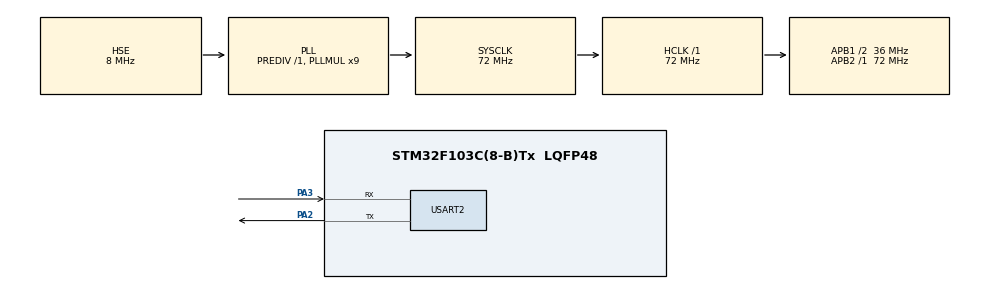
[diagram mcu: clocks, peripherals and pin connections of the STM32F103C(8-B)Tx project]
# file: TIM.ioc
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Mcu.Family=STM32F1
Mcu.Name=STM32F103C(8-B)Tx
Mcu.Package=LQFP48
NVIC.PriorityGroup=NVIC_PRIORITYGROUP_4
NVIC.TIM4_IRQn=true\:0\:0\:false\:false\:true\:true\:true\:true
NVIC.USART2_IRQn=true\:0\:0\:false\:false\:true\:true\:true\:true
PA13.Mode=Serial_Wire
PA13.Signal=SYS_JTMS-SWDIO
PA14.Mode=Serial_Wire
PA14.Signal=SYS_JTCK-SWCLK
PA2.Mode=Asynchronous
PA2.Signal=USART2_TX
PA3.Mode=Asynchronous
PA3.Signal=USART2_RX
PD0-OSC_IN.Mode=HSE-External-Oscillator
PD0-OSC_IN.Signal=RCC_OSC_IN
PD1-OSC_OUT.Mode=HSE-External-Oscillator
PD1-OSC_OUT.Signal=RCC_OSC_OUT
ProjectManager.HeapSize=0x200
ProjectManager.StackSize=0x400
ProjectManager.TargetToolchain=CMake
RCC.AHBFreq_Value=72000000
RCC.APB1CLKDivider=RCC_HCLK_DIV2
RCC.APB1Freq_Value=36000000
RCC.APB1TimFreq_Value=72000000
RCC.APB2Freq_Value=72000000
RCC.APB2TimFreq_Value=72000000
RCC.HCLKFreq_Value=72000000
RCC.PLLMUL=RCC_PLL_MUL9
RCC.PLLSourceVirtual=RCC_PLLSOURCE_HSE
RCC.SYSCLKFreq_VALUE=72000000
RCC.SYSCLKSource=RCC_SYSCLKSOURCE_PLLCLK
RCC.USBFreq_Value=72000000
TIM4.Period=10000-1
TIM4.Prescaler=7200-1
USART2.VirtualMode=VM_ASYNC
VP_TIM4_VS_ClockSourceINT.Mode=Internal
board=custom

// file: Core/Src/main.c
/* USER CODE BEGIN Header */
/**
  ******************************************************************************
  * @file           : main.c
  * @brief          : Main program body
  ******************************************************************************
  * @attention
  *
  * Copyright (c) 2026 STMicroelectronics.
  * All rights reserved.
  *
  * This software is licensed under terms that can be found in the LICENSE file
  * in the root directory of this software component.
  * If no LICENSE file comes with this software, it is provided AS-IS.
  *
  ******************************************************************************
  */
/* USER CODE END Header */
#include "main.h"

/* USER CODE BEGIN Includes */
#include "stdio.h"              /* 标准输入输出库，用于 sprintf 格式化字符串 */
#include "stm32f1xx_hal_tim.h"  /* TIM 定时器 HAL 库头文件 */
#include "string.h"             /* 字符串操作库，用于 strlen 获取字符串长度 */
/* USER CODE END Includes */

TIM_HandleTypeDef htim4;

UART_HandleTypeDef huart2;

void SystemClock_Config(void);
static void MX_GPIO_Init(void);
static void MX_TIM4_Init(void);
static void MX_USART2_UART_Init(void);

/* USER CODE BEGIN 0 */
char data[] = "一秒过去了";  /* 定时器溢出时通过串口发送的字符串 */

/* TIM 定时器溢出回调：每秒触发一次 */
void HAL_TIM_PeriodElapsedCallback(TIM_HandleTypeDef *htim){
  if(htim == &htim4){
    HAL_UART_Transmit_IT(&huart2, (uint8_t*)data, strlen(data));  /* 串口发送"一秒过去了" */
  }
}
/* USER CODE END 0 */

int main(void)
{

  /* MCU Configuration--------------------------------------------------------*/

  /* Reset of all peripherals, Initializes the Flash interface and the Systick. */
  HAL_Init();

  /* Configure the system clock */
  SystemClock_Config();

  /* Initialize all configured peripherals */
  MX_GPIO_Init();
  MX_TIM4_Init();
  MX_USART2_UART_Init();
  /* USER CODE BEGIN 2 */
  HAL_TIM_Base_Start_IT(&htim4);  /* 启动 TIM4 定时器，使能溢出中断（每1秒触发） */
  int counter = 0;                /* 定时器计数器值 */
  char message[20];               /* 串口发送缓冲区 */
  /* USER CODE END 2 */

  /* Infinite loop */
  /* USER CODE BEGIN WHILE */
  while (1)
  {
    counter = __HAL_TIM_GET_COUNTER(&htim4);            /* 读取 TIM4 当前计数值（0~9999） */
    sprintf(message, "Counter: %d", counter);           /* 格式化计数值字符串 */
    //HAL_UART_Transmit_IT(&huart2, (uint8_t*)message, strlen(message)); /* 串口输出（已注释） */
    HAL_Delay(99);                                      /* 每 99ms 读取一次 */
    /* USER CODE END WHILE */

  }
}

void SystemClock_Config(void)
{
  RCC_OscInitTypeDef RCC_OscInitStruct = {0};
  RCC_ClkInitTypeDef RCC_ClkInitStruct = {0};

  /** Initializes the RCC Oscillators according to the specified parameters
  * in the RCC_OscInitTypeDef structure.
  */
  RCC_OscInitStruct.OscillatorType = RCC_OSCILLATORTYPE_HSE;
  RCC_OscInitStruct.HSEState = RCC_HSE_ON;
  RCC_OscInitStruct.HSEPredivValue = RCC_HSE_PREDIV_DIV1;
  RCC_OscInitStruct.HSIState = RCC_HSI_ON;
  RCC_OscInitStruct.PLL.PLLState = RCC_PLL_ON;
  RCC_OscInitStruct.PLL.PLLSource = RCC_PLLSOURCE_HSE;
  RCC_OscInitStruct.PLL.PLLMUL = RCC_PLL_MUL9;
  if (HAL_RCC_OscConfig(&RCC_OscInitStruct) != HAL_OK)
  {
    Error_Handler();
  }

  /** Initializes the CPU, AHB and APB buses clocks
  */
  RCC_ClkInitStruct.ClockType = RCC_CLOCKTYPE_HCLK|RCC_CLOCKTYPE_SYSCLK
                              |RCC_CLOCKTYPE_PCLK1|RCC_CLOCKTYPE_PCLK2;
  RCC_ClkInitStruct.SYSCLKSource = RCC_SYSCLKSOURCE_PLLCLK;
  RCC_ClkInitStruct.AHBCLKDivider = RCC_SYSCLK_DIV1;
  RCC_ClkInitStruct.APB1CLKDivider = RCC_HCLK_DIV2;
  RCC_ClkInitStruct.APB2CLKDivider = RCC_HCLK_DIV1;

  if (HAL_RCC_ClockConfig(&RCC_ClkInitStruct, FLASH_LATENCY_2) != HAL_OK)
  {
    Error_Handler();
  }
}

static void MX_TIM4_Init(void)
{

  TIM_ClockConfigTypeDef sClockSourceConfig = {0};
  TIM_MasterConfigTypeDef sMasterConfig = {0};

  htim4.Instance = TIM4;
  htim4.Init.Prescaler = 7200-1;
  htim4.Init.CounterMode = TIM_COUNTERMODE_UP;
  htim4.Init.Period = 10000-1;
  htim4.Init.ClockDivision = TIM_CLOCKDIVISION_DIV1;
  htim4.Init.AutoReloadPreload = TIM_AUTORELOAD_PRELOAD_DISABLE;
  if (HAL_TIM_Base_Init(&htim4) != HAL_OK)
  {
    Error_Handler();
  }
  sClockSourceConfig.ClockSource = TIM_CLOCKSOURCE_INTERNAL;
  if (HAL_TIM_ConfigClockSource(&htim4, &sClockSourceConfig) != HAL_OK)
  {
    Error_Handler();
  }
  sMasterConfig.MasterOutputTrigger = TIM_TRGO_RESET;
  sMasterConfig.MasterSlaveMode = TIM_MASTERSLAVEMODE_DISABLE;
  if (HAL_TIMEx_MasterConfigSynchronization(&htim4, &sMasterConfig) != HAL_OK)
  {
    Error_Handler();
  }

}

static void MX_USART2_UART_Init(void)
{

  huart2.Instance = USART2;
  huart2.Init.BaudRate = 115200;
  huart2.Init.WordLength = UART_WORDLENGTH_8B;
  huart2.Init.StopBits = UART_STOPBITS_1;
  huart2.Init.Parity = UART_PARITY_NONE;
  huart2.Init.Mode = UART_MODE_TX_RX;
  huart2.Init.HwFlowCtl = UART_HWCONTROL_NONE;
  huart2.Init.OverSampling = UART_OVERSAMPLING_16;
  if (HAL_UART_Init(&huart2) != HAL_OK)
  {
    Error_Handler();
  }

}

static void MX_GPIO_Init(void)
{

  /* GPIO Ports Clock Enable */
  __HAL_RCC_GPIOD_CLK_ENABLE();
  __HAL_RCC_GPIOA_CLK_ENABLE();

}

void Error_Handler(void)
{
  __disable_irq();
  while (1)
  {
  }
}
